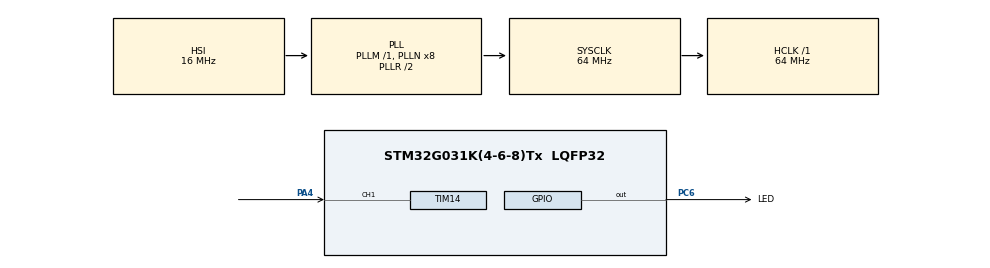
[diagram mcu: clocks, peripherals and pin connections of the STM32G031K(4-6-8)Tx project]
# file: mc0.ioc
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Mcu.Family=STM32G0
Mcu.Name=STM32G031K(4-6-8)Tx
Mcu.Package=LQFP32
NVIC.TIM14_IRQn=true\:0\:0\:false\:false\:true\:true\:true\:true
PA4.Signal=S_TIM14_CH1
PC6.GPIO_Label=LED
PC6.Signal=GPIO_Output
ProjectManager.HeapSize=0x200
ProjectManager.StackSize=0x400
ProjectManager.TargetToolchain=Makefile
RCC.ADCFreq_Value=64000000
RCC.AHBFreq_Value=64000000
RCC.CortexFreq_Value=64000000
RCC.EXTERNAL_CLOCK_VALUE=12288000
RCC.HCLKFreq_Value=64000000
RCC.HSE_VALUE=8000000
RCC.HSI_VALUE=16000000
RCC.LSE_VALUE=32768
RCC.SYSCLKFreq_VALUE=64000000
RCC.SYSCLKSource=RCC_SYSCLKSOURCE_PLLCLK
RCC.VCOOutputFreq_Value=128000000
SH.S_TIM14_CH1.0=TIM14_CH1,Input_Capture1_from_TI1
TIM14.Channel=TIM_CHANNEL_1
TIM14.ICPolarity_CH1=TIM_INPUTCHANNELPOLARITY_BOTHEDGE
TIM14.Prescaler=63
VP_TIM14_VS_ClockSourceINT.Mode=Enable_Timer
board=custom

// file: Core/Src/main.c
/* USER CODE BEGIN Header */
/**
  ******************************************************************************
  * @file           : main.c
  * @brief          : Main program body
  ******************************************************************************
  * @attention
  *
  * Copyright (c) 2026 STMicroelectronics.
  * All rights reserved.
  *
  * This software is licensed under terms that can be found in the LICENSE file
  * in the root directory of this software component.
  * If no LICENSE file comes with this software, it is provided AS-IS.
  *
  ******************************************************************************
  */
/* USER CODE END Header */
#include "main.h"

TIM_HandleTypeDef htim14;

void SystemClock_Config(void);
static void MX_GPIO_Init(void);
static void MX_TIM14_Init(void);

int main(void)
{

  /* MCU Configuration--------------------------------------------------------*/

  /* Reset of all peripherals, Initializes the Flash interface and the Systick. */
  HAL_Init();

  /* Configure the system clock */
  SystemClock_Config();

  /* Initialize all configured peripherals */
  MX_GPIO_Init();
  MX_TIM14_Init();
  /* USER CODE BEGIN 2 */
  HAL_TIM_IC_Start_IT(&htim14, TIM_CHANNEL_1);
  /* USER CODE END 2 */

  /* Infinite loop */
  /* USER CODE BEGIN WHILE */
  while (1)
  {
    HAL_GPIO_WritePin(LED_GPIO_Port, LED_Pin, GPIO_PIN_RESET);
    HAL_Delay(500);
    HAL_GPIO_WritePin(LED_GPIO_Port, LED_Pin, GPIO_PIN_SET);
    HAL_Delay(500);
    /* USER CODE END WHILE */

  }
}

void SystemClock_Config(void)
{
  RCC_OscInitTypeDef RCC_OscInitStruct = {0};
  RCC_ClkInitTypeDef RCC_ClkInitStruct = {0};

  /** Configure the main internal regulator output voltage
  */
  HAL_PWREx_ControlVoltageScaling(PWR_REGULATOR_VOLTAGE_SCALE1);

  /** Initializes the RCC Oscillators according to the specified parameters
  * in the RCC_OscInitTypeDef structure.
  */
  RCC_OscInitStruct.OscillatorType = RCC_OSCILLATORTYPE_HSI;
  RCC_OscInitStruct.HSIState = RCC_HSI_ON;
  RCC_OscInitStruct.HSIDiv = RCC_HSI_DIV1;
  RCC_OscInitStruct.HSICalibrationValue = RCC_HSICALIBRATION_DEFAULT;
  RCC_OscInitStruct.PLL.PLLState = RCC_PLL_ON;
  RCC_OscInitStruct.PLL.PLLSource = RCC_PLLSOURCE_HSI;
  RCC_OscInitStruct.PLL.PLLM = RCC_PLLM_DIV1;
  RCC_OscInitStruct.PLL.PLLN = 8;
  RCC_OscInitStruct.PLL.PLLP = RCC_PLLP_DIV2;
  RCC_OscInitStruct.PLL.PLLQ = RCC_PLLQ_DIV2;
  RCC_OscInitStruct.PLL.PLLR = RCC_PLLR_DIV2;
  if (HAL_RCC_OscConfig(&RCC_OscInitStruct) != HAL_OK)
  {
    Error_Handler();
  }

  /** Initializes the CPU, AHB and APB buses clocks
  */
  RCC_ClkInitStruct.ClockType = RCC_CLOCKTYPE_HCLK|RCC_CLOCKTYPE_SYSCLK
                              |RCC_CLOCKTYPE_PCLK1;
  RCC_ClkInitStruct.SYSCLKSource = RCC_SYSCLKSOURCE_PLLCLK;
  RCC_ClkInitStruct.AHBCLKDivider = RCC_SYSCLK_DIV1;
  RCC_ClkInitStruct.APB1CLKDivider = RCC_HCLK_DIV1;

  if (HAL_RCC_ClockConfig(&RCC_ClkInitStruct, FLASH_LATENCY_2) != HAL_OK)
  {
    Error_Handler();
  }
}

static void MX_TIM14_Init(void)
{

  TIM_IC_InitTypeDef sConfigIC = {0};

  htim14.Instance = TIM14;
  htim14.Init.Prescaler = 63;
  htim14.Init.CounterMode = TIM_COUNTERMODE_UP;
  htim14.Init.Period = 65535;
  htim14.Init.ClockDivision = TIM_CLOCKDIVISION_DIV1;
  htim14.Init.AutoReloadPreload = TIM_AUTORELOAD_PRELOAD_DISABLE;
  if (HAL_TIM_Base_Init(&htim14) != HAL_OK)
  {
    Error_Handler();
  }
  if (HAL_TIM_IC_Init(&htim14) != HAL_OK)
  {
    Error_Handler();
  }
  sConfigIC.ICPolarity = TIM_INPUTCHANNELPOLARITY_BOTHEDGE;
  sConfigIC.ICSelection = TIM_ICSELECTION_DIRECTTI;
  sConfigIC.ICPrescaler = TIM_ICPSC_DIV1;
  sConfigIC.ICFilter = 0;
  if (HAL_TIM_IC_ConfigChannel(&htim14, &sConfigIC, TIM_CHANNEL_1) != HAL_OK)
  {
    Error_Handler();
  }

}

static void MX_GPIO_Init(void)
{
  GPIO_InitTypeDef GPIO_InitStruct = {0};

  /* GPIO Ports Clock Enable */
  __HAL_RCC_GPIOA_CLK_ENABLE();
  __HAL_RCC_GPIOC_CLK_ENABLE();

  /*Configure GPIO pin Output Level */
  HAL_GPIO_WritePin(LED_GPIO_Port, LED_Pin, GPIO_PIN_RESET);

  /*Configure GPIO pin : LED_Pin */
  GPIO_InitStruct.Pin = LED_Pin;
  GPIO_InitStruct.Mode = GPIO_MODE_OUTPUT_PP;
  GPIO_InitStruct.Pull = GPIO_NOPULL;
  GPIO_InitStruct.Speed = GPIO_SPEED_FREQ_LOW;
  HAL_GPIO_Init(LED_GPIO_Port, &GPIO_InitStruct);

}

void Error_Handler(void)
{
  __disable_irq();
  while (1)
  {
  }
}
